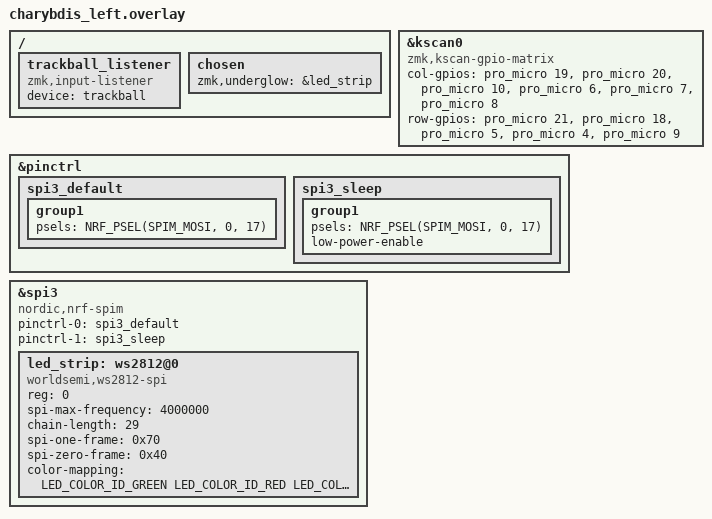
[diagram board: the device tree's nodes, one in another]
#include "charybdis.dtsi"
#include "charybdis_pmw3610.dtsi"
#include <dt-bindings/led/led.h>

&kscan0 {
	compatible = "zmk,kscan-gpio-matrix";

	col-gpios
		= <&pro_micro 19 (GPIO_ACTIVE_HIGH | GPIO_PULL_DOWN)>
		, <&pro_micro 20 (GPIO_ACTIVE_HIGH | GPIO_PULL_DOWN)>
		, <&pro_micro 10 (GPIO_ACTIVE_HIGH | GPIO_PULL_DOWN)>
		, <&pro_micro 6 (GPIO_ACTIVE_HIGH | GPIO_PULL_DOWN)>
		, <&pro_micro 7 (GPIO_ACTIVE_HIGH | GPIO_PULL_DOWN)>
		, <&pro_micro 8 (GPIO_ACTIVE_HIGH | GPIO_PULL_DOWN)>
		;

	row-gpios
   	        = <&pro_micro 21  GPIO_ACTIVE_HIGH>
                , <&pro_micro 18  GPIO_ACTIVE_HIGH>
                , <&pro_micro 5  GPIO_ACTIVE_HIGH>
                , <&pro_micro 4  GPIO_ACTIVE_HIGH>
                , <&pro_micro 9 GPIO_ACTIVE_HIGH>
                ;
};

// https://github.com/badjeff/zmk-pmw3610-driver
/ {
  trackball_listener {
    compatible = "zmk,input-listener";
    device = <&trackball>;
  };
};

// --- RGB Underglow (SK6812 MINI-E LEDs) ---
// DIN on P0.17, using spi3 (SPIM3 has 16-bit DMA counter for full chain)
&pinctrl {
    spi3_default: spi3_default {
        group1 {
            psels = <NRF_PSEL(SPIM_MOSI, 0, 17)>;
        };
    };

    spi3_sleep: spi3_sleep {
        group1 {
            psels = <NRF_PSEL(SPIM_MOSI, 0, 17)>;
            low-power-enable;
        };
    };
};

&spi3 {
    compatible = "nordic,nrf-spim";
    status = "okay";

    pinctrl-0 = <&spi3_default>;
    pinctrl-1 = <&spi3_sleep>;
    pinctrl-names = "default", "sleep";

    led_strip: ws2812@0 {
        compatible = "worldsemi,ws2812-spi";
        reg = <0>;
        spi-max-frequency = <4000000>;
        chain-length = <29>;
        spi-one-frame = <0x70>;
        spi-zero-frame = <0x40>;
        color-mapping = <LED_COLOR_ID_GREEN LED_COLOR_ID_RED LED_COLOR_ID_BLUE>;
    };
};

/ {
    chosen {
        zmk,underglow = &led_strip;
    };
};
